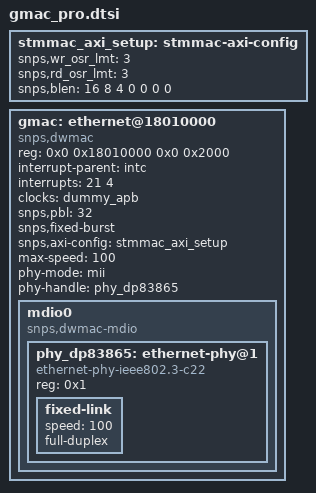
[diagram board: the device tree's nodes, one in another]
        stmmac_axi_setup: stmmac-axi-config{
			snps,wr_osr_lmt = <3>;
			snps,rd_osr_lmt = <3>;
			snps,blen = <16 8 4 0 0 0 0> ;
		};
		gmac: ethernet@18010000 {
			compatible = "snps,dwmac";
			reg = <0x0 0x18010000 0x0 0x2000>;
			interrupt-parent = <&intc>;
			interrupts = <21 4>;
			interrupt-names = "macirq";
			clocks = <&dummy_apb>;
			clock-names = "stmmaceth";
			snps,pbl = <32>;
			snps,fixed-burst;
			snps,axi-config = <&stmmac_axi_setup>;
			max-speed = <100>;
			phy-mode = "mii";
			phy-handle = <&phy_dp83865>;
			mdio0 {
				#address-cells = <1>;
				#size-cells = <0>;
				compatible = "snps,dwmac-mdio";

				phy_dp83865: ethernet-phy@1 {
					compatible = "ethernet-phy-ieee802.3-c22";
					reg = <0x1>;
					fixed-link {
						speed = <100>;
						full-duplex;
					};
				};
			};
		};
